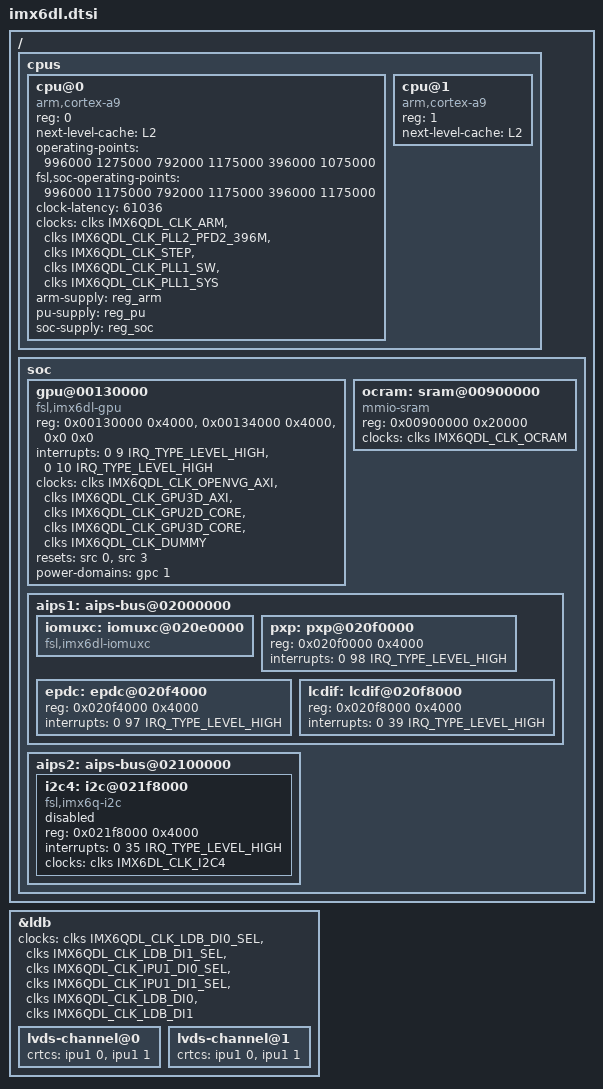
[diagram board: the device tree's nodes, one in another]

/*
 * Copyright 2013 Freescale Semiconductor, Inc.
 *
 * This program is free software; you can redistribute it and/or modify
 * it under the terms of the GNU General Public License version 2 as
 * published by the Free Software Foundation.
 *
 */

#include <dt-bindings/interrupt-controller/irq.h>
#include "imx6dl-pinfunc.h"
#include "imx6qdl.dtsi"

/ {
	cpus {
		#address-cells = <1>;
		#size-cells = <0>;

		cpu@0 {
			compatible = "arm,cortex-a9";
			device_type = "cpu";
			reg = <0>;
			next-level-cache = <&L2>;
			operating-points = <
				/* kHz    uV */
				996000  1275000
				792000  1175000
				396000  1075000
			>;
			fsl,soc-operating-points = <
				/* ARM kHz  SOC-PU uV */
				996000	1175000
				792000	1175000
				396000	1175000
			>;
			clock-latency = <61036>; /* two CLK32 periods */
			clocks = <&clks IMX6QDL_CLK_ARM>,
				 <&clks IMX6QDL_CLK_PLL2_PFD2_396M>,
				 <&clks IMX6QDL_CLK_STEP>,
				 <&clks IMX6QDL_CLK_PLL1_SW>,
				 <&clks IMX6QDL_CLK_PLL1_SYS>;
			clock-names = "arm", "pll2_pfd2_396m", "step",
				      "pll1_sw", "pll1_sys";
			arm-supply = <&reg_arm>;
			pu-supply = <&reg_pu>;
			soc-supply = <&reg_soc>;
		};

		cpu@1 {
			compatible = "arm,cortex-a9";
			device_type = "cpu";
			reg = <1>;
			next-level-cache = <&L2>;
		};
	};

	soc {
		gpu@00130000 {
			compatible = "fsl,imx6dl-gpu", "fsl,imx6q-gpu";
			reg = <0x00130000 0x4000>, <0x00134000 0x4000>,
			      <0x0 0x0>;
			reg-names = "iobase_3d", "iobase_2d",
				    "phys_baseaddr";
			interrupts = <0 9 IRQ_TYPE_LEVEL_HIGH>,
				     <0 10 IRQ_TYPE_LEVEL_HIGH>;
			interrupt-names = "irq_3d", "irq_2d";
			clocks = <&clks IMX6QDL_CLK_OPENVG_AXI>, <&clks IMX6QDL_CLK_GPU3D_AXI>,
				 <&clks IMX6QDL_CLK_GPU2D_CORE>, <&clks IMX6QDL_CLK_GPU3D_CORE>,
				 <&clks IMX6QDL_CLK_DUMMY>;
			clock-names = "gpu2d_axi_clk", "gpu3d_axi_clk",
				      "gpu2d_clk", "gpu3d_clk",
				      "gpu3d_shader_clk";
			resets = <&src 0>, <&src 3>;
			reset-names = "gpu3d", "gpu2d";
			power-domains = <&gpc 1>;
		};

		ocram: sram@00900000 {
			compatible = "mmio-sram";
			reg = <0x00900000 0x20000>;
			clocks = <&clks IMX6QDL_CLK_OCRAM>;
		};

		aips1: aips-bus@02000000 {
			iomuxc: iomuxc@020e0000 {
				compatible = "fsl,imx6dl-iomuxc";
			};

			pxp: pxp@020f0000 {
				reg = <0x020f0000 0x4000>;
				interrupts = <0 98 IRQ_TYPE_LEVEL_HIGH>;
			};

			epdc: epdc@020f4000 {
				reg = <0x020f4000 0x4000>;
				interrupts = <0 97 IRQ_TYPE_LEVEL_HIGH>;
			};

			lcdif: lcdif@020f8000 {
				reg = <0x020f8000 0x4000>;
				interrupts = <0 39 IRQ_TYPE_LEVEL_HIGH>;
			};
		};

		aips2: aips-bus@02100000 {
			i2c4: i2c@021f8000 {
				#address-cells = <1>;
				#size-cells = <0>;
				compatible = "fsl,imx6q-i2c", "fsl,imx21-i2c";
				reg = <0x021f8000 0x4000>;
				interrupts = <0 35 IRQ_TYPE_LEVEL_HIGH>;
				clocks = <&clks IMX6DL_CLK_I2C4>;
				status = "disabled";
			};
		};
	};
};

&ldb {
	clocks = <&clks IMX6QDL_CLK_LDB_DI0_SEL>, <&clks IMX6QDL_CLK_LDB_DI1_SEL>,
		 <&clks IMX6QDL_CLK_IPU1_DI0_SEL>, <&clks IMX6QDL_CLK_IPU1_DI1_SEL>,
		 <&clks IMX6QDL_CLK_LDB_DI0>, <&clks IMX6QDL_CLK_LDB_DI1>;
	clock-names = "di0_pll", "di1_pll",
		      "di0_sel", "di1_sel",
		      "di0", "di1";

	lvds-channel@0 {
		crtcs = <&ipu1 0>, <&ipu1 1>;
	};

	lvds-channel@1 {
		crtcs = <&ipu1 0>, <&ipu1 1>;
	};
};
